AUTOSAR XML (schema 00047)
package /Svc_Det/ClientServerInterfaces
  client server interface DETService: is-service=true, service-kind=DEVELOPMENT-ERROR-TRACER
    operation ReportError: possible-error=E_OK
      arg ApiId: type=uint8, direction=IN, server-argument-impl-policy=USE-ARGUMENT-TYPE
      arg ErrorId: type=uint8, direction=IN, server-argument-impl-policy=USE-ARGUMENT-TYPE
    operation ReportRuntimeError: possible-error=E_OK
      arg ApiId: type=uint8, direction=IN, server-argument-impl-policy=USE-ARGUMENT-TYPE
      arg ErrorId: type=uint8, direction=IN, server-argument-impl-policy=USE-ARGUMENT-TYPE
    error E_OK: error-code=0
package /Svc_Det/ServiceSwComponentTypes
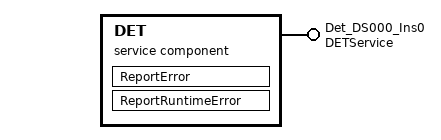
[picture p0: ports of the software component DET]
  service sw component type DET
    provide port Det_DS000_Ins0: provided-com-specs=[{operation=ReportError, queue-length=1}, {operation=ReportRuntimeError, queue-length=1}], provided-interface=DETService
    behavior DetInternalBehavior: handle-termination-and-restart=NO-SUPPORT, port-api-option{enable-take-address=true, indirect-api=false, port-arg-values=[{value=4096, value-type=uint16}, {value=0, value-type=uint8}], port=Det_DS000_Ins0}
      operation invoked event OIE_Det_DS000_Ins0_ReportError: start-on-event=ReportError, operation=Det_DS000_Ins0.ReportError
      operation invoked event OIE_Det_DS000_Ins0_ReportRuntimeError: start-on-event=ReportRuntimeError, operation=Det_DS000_Ins0.ReportRuntimeError
      runnable ReportError: can-be-invoked-concurrently=true, symbol=Det_ReportError
      runnable ReportRuntimeError: can-be-invoked-concurrently=true, symbol=Det_ReportRuntimeError
  swc implementation Det_SwcImplementation: programming-language=C, sw-version=1.0.0, swc-bsw-mapping=SwcBswMapping_Det, vendor-id=76, behavior=DetInternalBehavior
    code-descriptors:
      code CodeDescriptor: artifact-descriptors=autosar-engineering-object={short-label=Det_LibObjects, category=SWLIB, domain=AUTOSAR_DET}
    resource consumption ResourceConsumption
  swc bsw mapping SwcBswMapping_Det: bsw-behavior=BswInternalBehavior_Det, swc-behavior=DetInternalBehavior
    runnable-mappings:
      bsw-entity=BswCE_Det_ReportError, swc-runnable=ReportError
      bsw-entity=BswCE_Det_ReportRuntimeError, swc-runnable=ReportRuntimeError
